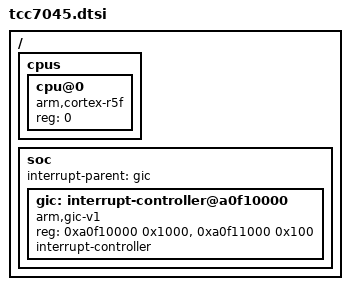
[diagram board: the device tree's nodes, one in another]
/*
 * Copyright 2024 Hounjoung Rim <hounjoung@tsnlab.com>
 *
 * SPDX-License-Identifier: Apache-2.0
 */

#include <arm/tcc/tcc70xx.dtsi>

/ {
	cpus {
		#address-cells = <1>;
		#size-cells = <0>;

		cpu@0 {
			device_type = "cpu";
			compatible = "arm,cortex-r5f";
			reg = <0>;
		};
	};

	soc {

		interrupt-parent = <&gic>;

		gic: interrupt-controller@a0f10000 {
			compatible = "arm,gic-v1", "arm,gic";
			reg = <0xa0f10000 0x1000>,
			        <0xa0f11000 0x100>;
			interrupt-controller;
			#interrupt-cells = <4>;
			status = "okay";
		};
	};
};
